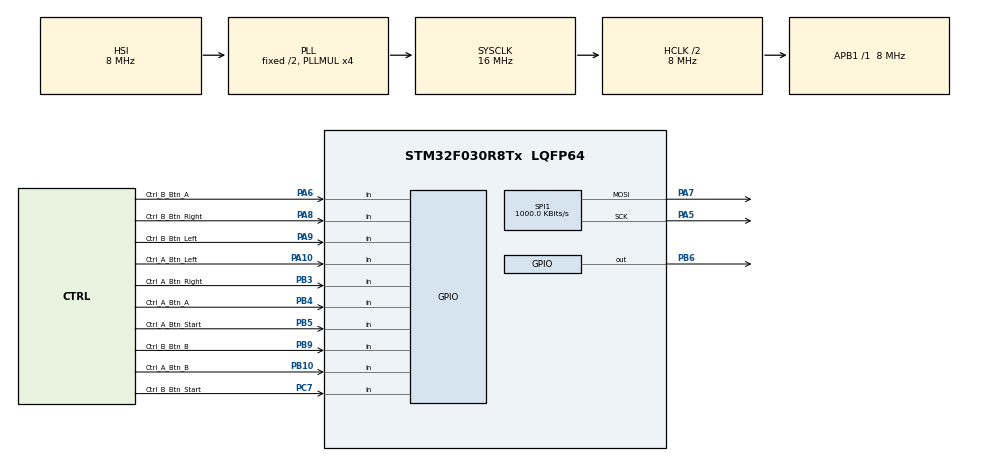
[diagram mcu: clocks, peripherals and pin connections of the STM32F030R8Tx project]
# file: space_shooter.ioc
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Mcu.Family=STM32F0
Mcu.Name=STM32F030R8Tx
Mcu.Package=LQFP64
PA10.GPIO_Label=Ctrl_A_Btn_Left
PA10.GPIO_PuPd=GPIO_PULLUP
PA10.Signal=GPIO_Input
PA13.GPIO_Label=TMS
PA13.Mode=Serial_Wire
PA13.Signal=SYS_SWDIO
PA14.GPIO_Label=TCK
PA14.Mode=Serial_Wire
PA14.Signal=SYS_SWCLK
PA5.Mode=TX_Only_Simplex_Unidirect_Master
PA5.Signal=SPI1_SCK
PA6.GPIO_Label=Ctrl_B_Btn_A
PA6.GPIO_PuPd=GPIO_PULLUP
PA6.Signal=GPIO_Input
PA7.Mode=TX_Only_Simplex_Unidirect_Master
PA7.Signal=SPI1_MOSI
PA8.GPIO_Label=Ctrl_B_Btn_Right
PA8.GPIO_PuPd=GPIO_PULLUP
PA8.Signal=GPIO_Input
PA9.GPIO_Label=Ctrl_B_Btn_Left
PA9.GPIO_PuPd=GPIO_PULLUP
PA9.Signal=GPIO_Input
PB10.GPIO_Label=Ctrl_A_Btn_B
PB10.GPIO_PuPd=GPIO_PULLUP
PB10.Signal=GPIO_Input
PB3.GPIO_Label=Ctrl_A_Btn_Right
PB3.GPIO_PuPd=GPIO_PULLUP
PB3.Signal=GPIO_Input
PB4.GPIO_Label=Ctrl_A_Btn_A
PB4.GPIO_PuPd=GPIO_PULLUP
PB4.Signal=GPIO_Input
PB5.GPIO_Label=Ctrl_A_Btn_Start
PB5.GPIO_PuPd=GPIO_PULLUP
PB5.Signal=GPIO_Input
PB6.PinState=GPIO_PIN_RESET
PB6.Signal=GPIO_Output
PB9.GPIO_Label=Ctrl_B_Btn_B
PB9.GPIO_PuPd=GPIO_PULLUP
PB9.Signal=GPIO_Input
PC7.GPIO_Label=Ctrl_B_Btn_Start
PC7.GPIO_PuPd=GPIO_PULLUP
PC7.Signal=GPIO_Input
ProjectManager.HeapSize=0x100
ProjectManager.StackSize=0x300
ProjectManager.TargetToolchain=STM32CubeIDE
RCC.AHBCLKDivider=RCC_SYSCLK_DIV2
RCC.AHBFreq_Value=8000000
RCC.APB1Freq_Value=8000000
RCC.APB1TimFreq_Value=8000000
RCC.HCLKFreq_Value=8000000
RCC.PLLMUL=RCC_PLL_MUL4
RCC.SYSCLKFreq_VALUE=16000000
RCC.SYSCLKSource=RCC_SYSCLKSOURCE_PLLCLK
SPI1.BaudRatePrescaler=SPI_BAUDRATEPRESCALER_8
SPI1.CalculateBaudRate=1000.0 KBits/s
SPI1.DataSize=SPI_DATASIZE_8BIT
SPI1.Direction=SPI_DIRECTION_2LINES
SPI1.Mode=SPI_MODE_MASTER
SPI1.VirtualType=VM_MASTER
board=NUCLEO-F030R8

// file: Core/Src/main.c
/* USER CODE BEGIN Header */
/**
  ******************************************************************************
  * @file           : main.c
  * @brief          : Main program body
  ******************************************************************************
  * @attention
  *
  * Copyright (c) 2022 STMicroelectronics.
  * All rights reserved.
  *
  * This software is licensed under terms that can be found in the LICENSE file
  * in the root directory of this software component.
  * If no LICENSE file comes with this software, it is provided AS-IS.
  *
  ******************************************************************************
  */
/* USER CODE END Header */
#include "main.h"

/* USER CODE BEGIN Includes */
#include <stdio.h>
#include <string.h>
#include <stdbool.h>

/* USER CODE END Includes */

 SPI_HandleTypeDef hspi1;

void SystemClock_Config(void);
static void MX_GPIO_Init(void);
static void MX_SPI1_Init(void);

int main(void)
{

  /* MCU Configuration--------------------------------------------------------*/

  /* Reset of all peripherals, Initializes the Flash interface and the Systick. */
  HAL_Init();

  /* Configure the system clock */
  SystemClock_Config();

  /* Initialize all configured peripherals */
  MX_GPIO_Init();
  MX_SPI1_Init();

  /* Infinite loop */
  /* USER CODE BEGIN WHILE */
  while (1)
  {
	  cppMain(&hspi1);

    /* USER CODE END WHILE */

  }
}

void SystemClock_Config(void)
{
  RCC_OscInitTypeDef RCC_OscInitStruct = {0};
  RCC_ClkInitTypeDef RCC_ClkInitStruct = {0};

  /** Initializes the RCC Oscillators according to the specified parameters
  * in the RCC_OscInitTypeDef structure.
  */
  RCC_OscInitStruct.OscillatorType = RCC_OSCILLATORTYPE_HSI;
  RCC_OscInitStruct.HSIState = RCC_HSI_ON;
  RCC_OscInitStruct.HSICalibrationValue = RCC_HSICALIBRATION_DEFAULT;
  RCC_OscInitStruct.PLL.PLLState = RCC_PLL_ON;
  RCC_OscInitStruct.PLL.PLLSource = RCC_PLLSOURCE_HSI;
  RCC_OscInitStruct.PLL.PLLMUL = RCC_PLL_MUL4;
  RCC_OscInitStruct.PLL.PREDIV = RCC_PREDIV_DIV1;
  if (HAL_RCC_OscConfig(&RCC_OscInitStruct) != HAL_OK)
  {
    Error_Handler();
  }

  /** Initializes the CPU, AHB and APB buses clocks
  */
  RCC_ClkInitStruct.ClockType = RCC_CLOCKTYPE_HCLK|RCC_CLOCKTYPE_SYSCLK
                              |RCC_CLOCKTYPE_PCLK1;
  RCC_ClkInitStruct.SYSCLKSource = RCC_SYSCLKSOURCE_PLLCLK;
  RCC_ClkInitStruct.AHBCLKDivider = RCC_SYSCLK_DIV2;
  RCC_ClkInitStruct.APB1CLKDivider = RCC_HCLK_DIV1;

  if (HAL_RCC_ClockConfig(&RCC_ClkInitStruct, FLASH_LATENCY_0) != HAL_OK)
  {
    Error_Handler();
  }
}

static void MX_SPI1_Init(void)
{

  /* SPI1 parameter configuration*/
  hspi1.Instance = SPI1;
  hspi1.Init.Mode = SPI_MODE_MASTER;
  hspi1.Init.Direction = SPI_DIRECTION_2LINES;
  hspi1.Init.DataSize = SPI_DATASIZE_8BIT;
  hspi1.Init.CLKPolarity = SPI_POLARITY_LOW;
  hspi1.Init.CLKPhase = SPI_PHASE_1EDGE;
  hspi1.Init.NSS = SPI_NSS_SOFT;
  hspi1.Init.BaudRatePrescaler = SPI_BAUDRATEPRESCALER_8;
  hspi1.Init.FirstBit = SPI_FIRSTBIT_MSB;
  hspi1.Init.TIMode = SPI_TIMODE_DISABLE;
  hspi1.Init.CRCCalculation = SPI_CRCCALCULATION_DISABLE;
  hspi1.Init.CRCPolynomial = 7;
  hspi1.Init.CRCLength = SPI_CRC_LENGTH_DATASIZE;
  hspi1.Init.NSSPMode = SPI_NSS_PULSE_ENABLE;
  if (HAL_SPI_Init(&hspi1) != HAL_OK)
  {
    Error_Handler();
  }

}

static void MX_GPIO_Init(void)
{
  GPIO_InitTypeDef GPIO_InitStruct = {0};

  /* GPIO Ports Clock Enable */
  __HAL_RCC_GPIOA_CLK_ENABLE();
  __HAL_RCC_GPIOB_CLK_ENABLE();
  __HAL_RCC_GPIOC_CLK_ENABLE();

  /*Configure GPIO pin Output Level */
  HAL_GPIO_WritePin(GPIOB, GPIO_PIN_6, GPIO_PIN_RESET);

  /*Configure GPIO pins : Ctrl_B_Btn_A_Pin Ctrl_B_Btn_Right_Pin Ctrl_B_Btn_Left_Pin Ctrl_A_Btn_Left_Pin */
  GPIO_InitStruct.Pin = Ctrl_B_Btn_A_Pin|Ctrl_B_Btn_Right_Pin|Ctrl_B_Btn_Left_Pin|Ctrl_A_Btn_Left_Pin;
  GPIO_InitStruct.Mode = GPIO_MODE_INPUT;
  GPIO_InitStruct.Pull = GPIO_PULLUP;
  HAL_GPIO_Init(GPIOA, &GPIO_InitStruct);

  /*Configure GPIO pins : Ctrl_A_Btn_B_Pin Ctrl_A_Btn_Right_Pin Ctrl_A_Btn_A_Pin Ctrl_A_Btn_Start_Pin
                           Ctrl_B_Btn_B_Pin */
  GPIO_InitStruct.Pin = Ctrl_A_Btn_B_Pin|Ctrl_A_Btn_Right_Pin|Ctrl_A_Btn_A_Pin|Ctrl_A_Btn_Start_Pin
                          |Ctrl_B_Btn_B_Pin;
  GPIO_InitStruct.Mode = GPIO_MODE_INPUT;
  GPIO_InitStruct.Pull = GPIO_PULLUP;
  HAL_GPIO_Init(GPIOB, &GPIO_InitStruct);

  /*Configure GPIO pin : Ctrl_B_Btn_Start_Pin */
  GPIO_InitStruct.Pin = Ctrl_B_Btn_Start_Pin;
  GPIO_InitStruct.Mode = GPIO_MODE_INPUT;
  GPIO_InitStruct.Pull = GPIO_PULLUP;
  HAL_GPIO_Init(Ctrl_B_Btn_Start_GPIO_Port, &GPIO_InitStruct);

  /*Configure GPIO pin : PB6 */
  GPIO_InitStruct.Pin = GPIO_PIN_6;
  GPIO_InitStruct.Mode = GPIO_MODE_OUTPUT_PP;
  GPIO_InitStruct.Pull = GPIO_NOPULL;
  GPIO_InitStruct.Speed = GPIO_SPEED_FREQ_LOW;
  HAL_GPIO_Init(GPIOB, &GPIO_InitStruct);

}

void Error_Handler(void)
{
  __disable_irq();
  while (1)
  {
  }
}
